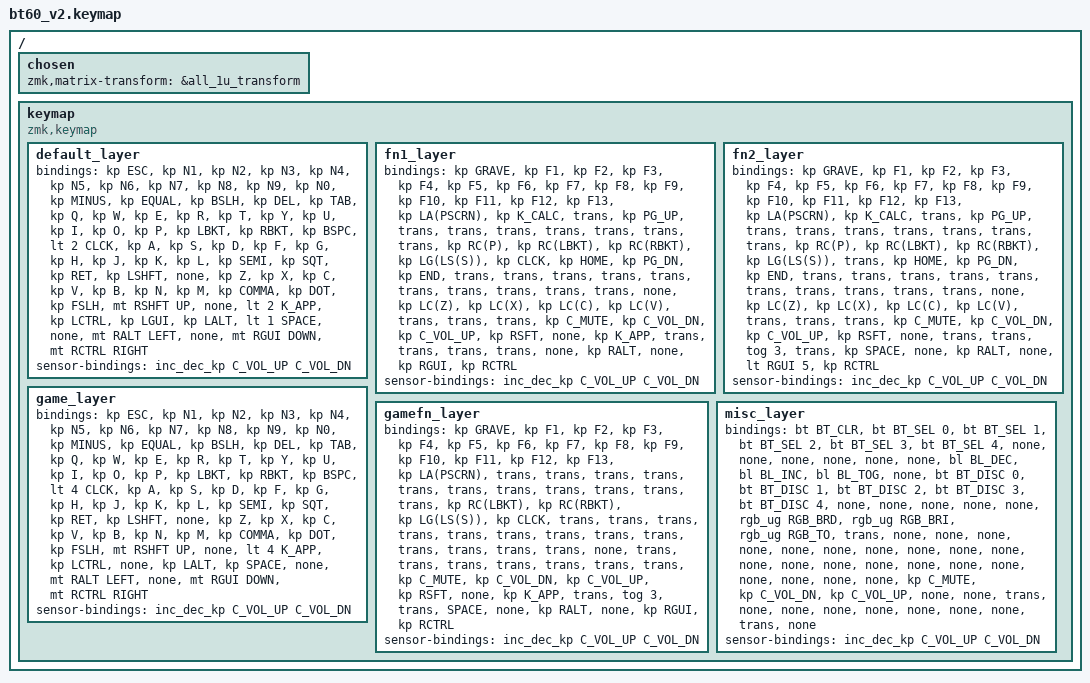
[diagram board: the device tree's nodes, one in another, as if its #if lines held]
#include <behaviors.dtsi>
#include <dt-bindings/zmk/keys.h>
#include <dt-bindings/zmk/bt.h>
#include <dt-bindings/zmk/rgb.h>
#include <dt-bindings/zmk/backlight.h>

#define ALL_1U
#define DEFAULT 0
#define FN1 1
#define FN2 2
#define GAME 3
#define GAMEFN 4
#define MISC 5

/ {
  chosen {
  #ifdef ALL_1U
    zmk,matrix-transform = &all_1u_transform;
  #else
  #error "Layout not defined, please define a layout by uncommenting the appropriate line in bt60_v2.keymap"
  #endif
  };

  keymap {
    compatible = "zmk,keymap";
    #ifdef ANSI
    default_layer {
        // ------------------------------------------------------------------------------------------0
        // | ESC |  1  |  2  |  3  |  4  |  5  |  6  |  7  |  8  |  9  |  0  |  -  |  =  |  \  | DEL |
        // | TAB   |  Q  |  W  |  E  |  R  |  T  |  Y  |  U  |  I  |  O  |  P  |  [  |  ]  |   BSPC  |
        // |  2,CAPS  |  A  |  S  |  D  |  F  |  G  |  H  |  J  |  K  |  L  |  ;  |  '  |    ENTER   |
        // | SHFT |NONE|  Z  |  X  |  C  |  V  |  B  |  N  |  M  |  ,  |  .  | / | SHFT, UP | NONE |  2,APP |
        // |  CTL  |  WIN  |  ALT  |     1,SPACE      | NONE| ALT,LEFT | NONE | WIN,DOWN | CTL,RIGHT |
        // ------------------------------------------------------------------------------------------
      bindings = <
        &kp ESC &kp N1 &kp N2 &kp N3 &kp N4 &kp N5 &kp N6 &kp N7 &kp  N8   &kp  N9 &kp  N0  &kp MINUS &kp EQUAL &kp BSLH &kp DEL
        &kp TAB  &kp Q  &kp W  &kp E  &kp R  &kp T  &kp Y  &kp U  &kp  I    &kp  O  &kp  P   &kp LBKT &kp RBKT  &kp BSPC
        &lt 2 CLCK  &kp A  &kp S  &kp D  &kp F  &kp G  &kp H  &kp J  &kp  K    &kp  L  &kp SEMI &kp SQT           &kp RET
        &kp LSHFT &none  &kp Z  &kp X  &kp C  &kp V  &kp B  &kp N  &kp M  &kp COMMA &kp DOT &kp FSLH    &mt RSHFT UP  &none &lt 2 K_APP
        &kp LCTRL &kp LGUI &kp LALT            &lt 1 SPACE                           &none &mt RALT LEFT &none &mt RGUI DOWN &mt RCTRL RIGHT
      >;
      sensor-bindings = <&inc_dec_kp C_VOL_UP C_VOL_DN>;
    };
    fn1_layer {
        // ------------------------------------------------------------------------------------------1
        // |GRAVE| F1  | F2  | F3  | F4  | F5  | F6  | F7  | F8  | F9  | F10 | F11 | F12 | F13 | A_PSCR |
        // | CALC  |  Q  |  PGUP  |  E  | R | T |  Y  |  U  | I |  O  | C_P | [ | ] | WIN+SHFT+S  |
        // | CAPS  |  HOME  |  PGDN  |  END  | F | G |  H  |  J  |  K  |  L  | ; | ' |      ENTER     |
        // | SHFT |NONE| C_Z | C_X | C_C | C_V | B |  N  |  M  |  MUTE  | VOLDN | VOLUP | SHFT| NONE | APP  |
        // | CTRL| WIN|  ALT  |           SPACE              | NONE| ALT | NONE |WIN| CTRL|
        // ------------------------------------------------------------------------------------------
      bindings = <
        &kp GRAVE &kp F1 &kp F2 &kp F3 &kp F4 &kp F5 &kp F6 &kp F7 &kp  F8   &kp  F9 &kp  F10  &kp F11 &kp F12   &kp F13 &kp LA(PSCRN)
        &kp K_CALC &trans &kp PG_UP &trans &trans &trans &trans &trans &trans &trans &kp RC(P) &kp RC(LBKT) &kp RC(RBKT) &kp LG(LS(S))
        &kp CLCK    &kp HOME &kp PG_DN &kp END &trans &trans &trans &trans &trans &trans &trans  &trans   &trans
        &trans &none &kp LC(Z) &kp LC(X) &kp LC(C) &kp LC(V) &trans &trans &trans &kp C_MUTE &kp C_VOL_DN &kp C_VOL_UP &kp RSFT &none &kp K_APP
        &trans &trans  &trans              &trans                            &none  &kp RALT &none   &kp RGUI &kp RCTRL
      >;
      sensor-bindings = <&inc_dec_kp C_VOL_UP C_VOL_DN>;
    };
    fn2_layer {
        // ------------------------------------------------------------------------------------------2
        // |GRAVE| F1  | F2  | F3  | F4  | F5  | F6  | F7  | F8  | F9  | F10 | F11 | F12 | F13 | A_PSCR |
        // | CALC  |  Q  |  PGUP  |  E  | R | T |  Y  |  U  | I |  O  | C_P | [ | ] | WIN+SHFT+S  |
        // | CAPS  |  HOME  |  PGDN  |  END  | F | G |  H  |  J  |  K  |  L  | ; | ' |      ENTER     |
        // | SHFT |NONE| C_Z | C_X | C_C | C_V | B |  N  |  M  |  MUTE  | VOLDN | VOLUP | SHFT| NONE | APP  |
        // | CTRL| 3 |  ALT  |           SPACE              | NONE| ALT | NONE |5,WIN| CTRL|
        // ------------------------------------------------------------------------------------------
      bindings = <
        &kp GRAVE &kp F1 &kp F2 &kp F3 &kp F4 &kp F5 &kp F6 &kp F7 &kp  F8   &kp  F9 &kp  F10  &kp F11 &kp F12   &kp F13 &kp LA(PSCRN)
        &kp K_CALC &trans &kp PG_UP &trans &trans &trans &trans &trans &trans &trans &kp RC(P) &kp RC(LBKT) &kp RC(RBKT) &kp LG(LS(S))
        &trans    &kp HOME &kp PG_DN &kp END &trans &trans &trans &trans &trans &trans &trans  &trans   &trans
        &trans &none &kp LC(Z) &kp LC(X) &kp LC(C) &kp LC(V) &trans &trans &trans &kp C_MUTE &kp C_VOL_DN &kp C_VOL_UP &kp RSFT &none &trans
        &trans &tog 3  &trans              &kp SPACE                            &none  &kp RALT &none   &lt RGUI 5 &kp RCTRL
      >;
      sensor-bindings = <&inc_dec_kp C_VOL_UP C_VOL_DN>;
    };
    game_layer {
        // ------------------------------------------------------------------------------------------3
        // | ESC |  1  |  2  |  3  |  4  |  5  |  6  |  7  |  8  |  9  |  0  |  -  |  =  |  \  | DEL |
        // | TAB   |  Q  |  W  |  E  |  R  |  T  |  Y  |  U  |  I  |  O  |  P  |  [  |  ]  |   BSPC  |
        // |  4,CAPS  |  A  |  S  |  D  |  F  |  G  |  H  |  J  |  K  |  L  |  ;  |  '  |    ENTER   |
        // | SHFT |NONE|  Z  |  X  |  C  |  V  |  B  |  N  |  M  |  ,  |  .  | / | SHFT, UP | NONE |  4,APP |
        // |  CTL  |  NONE  |  ALT  |     SPACE      | NONE| ALT,LEFT | NONE | WIN,DOWN | CTL,RIGHT |
        // ------------------------------------------------------------------------------------------
      bindings = <
        &kp ESC &kp N1 &kp N2 &kp N3 &kp N4 &kp N5 &kp N6 &kp N7 &kp  N8   &kp  N9 &kp  N0  &kp MINUS &kp EQUAL &kp BSLH &kp DEL
        &kp TAB  &kp Q  &kp W  &kp E  &kp R  &kp T  &kp Y  &kp U  &kp  I    &kp  O  &kp  P   &kp LBKT &kp RBKT  &kp BSPC
        &lt 4 CLCK  &kp A  &kp S  &kp D  &kp F  &kp G  &kp H  &kp J  &kp  K    &kp  L  &kp SEMI &kp SQT           &kp RET
        &kp LSHFT &none  &kp Z  &kp X  &kp C  &kp V  &kp B  &kp N  &kp M  &kp COMMA &kp DOT &kp FSLH    &mt RSHFT UP  &none &lt 4 K_APP
        &kp LCTRL &none &kp LALT            &kp SPACE                           &none &mt RALT LEFT &none &mt RGUI DOWN &mt RCTRL RIGHT
      >;
      sensor-bindings = <&inc_dec_kp C_VOL_UP C_VOL_DN>;
    };
    gamefn_layer {
        // ------------------------------------------------------------------------------------------4
        // |GRAVE| F1  | F2  | F3  | F4  | F5  | F6  | F7  | F8  | F9  | F10 | F11 | F12 | F13 | A_PSCR |
        // | TAB  |  Q  |  W  |  E  | R | T |  Y  |  U  | I |  O  | P | C[ | C] | WIN+SHFT+S  |
        // | CAPS  |  A  |  S  |  D  | F | G |  H  |  J  |  K  |  L  | ; | ' |      ENTER     |
        // | SHFT |NONE| Z | X | C | V | B |  N  |  M  |  MUTE  | VOLDN | VOLUP | SHFT| NONE | APP  |
        // | CTRL| 0 |  ALT  |           SPACE              | NONE| ALT | NONE |WIN| CTRL|
        // ------------------------------------------------------------------------------------------
      bindings = <
        &kp GRAVE &kp F1 &kp F2 &kp F3 &kp F4 &kp F5 &kp F6 &kp F7 &kp  F8   &kp  F9 &kp  F10  &kp F11 &kp F12   &kp F13 &kp LA(PSCRN)
        &trans &trans &trans &trans &trans &trans &trans &trans &trans &trans &trans &kp RC(LBKT) &kp RC(RBKT) &kp LG(LS(S))
        &kp CLCK    &trans &trans &trans &trans &trans &trans &trans &trans &trans &trans  &trans   &trans
        &trans &none &trans &trans &trans &trans &trans &trans &trans &kp C_MUTE &kp C_VOL_DN &kp C_VOL_UP &kp RSFT &none &kp K_APP
        &trans &tog 3  &trans              &SPACE                           &none  &kp RALT &none   &kp RGUI &kp RCTRL
      >;
      sensor-bindings = <&inc_dec_kp C_VOL_UP C_VOL_DN>;
    };
    misc_layer {
        // ------------------------------------------------------------------------------------------4
        // |BTCLR| BT0  | BT1  | BT2  | BT3  | BT4  | F6  | F7  | F8  | F9  | F10 | F11 | BL_DEC | BL_INC | BL_TOG |
        // | TAB  |  Q  |  W  |  E  | R | T |  Y  |  U  | I |  O  | P | RGB_BRD | RGB_BRI | RGB_TOG  |
        // | CAPS  |  A  |  S  |  D  | F | G |  H  |  J  |  K  |  L  | ; | ' |      ENTER     |
        // | SHFT |NONE| Z | X | C | V | B |  N  |  M  |  MUTE  | VOLDN | VOLUP | SHFT| NONE | APP  |
        // | CTRL| 0 |  ALT  |           SPACE              | NONE| ALT | NONE |WIN| CTRL|
        // ------------------------------------------------------------------------------------------
      bindings = <
        &bt BT_CLR &bt BT_SEL 0 &bt BT_SEL 1 &bt BT_SEL 2 &bt BT_SEL 3 &bt BT_SEL 4 &none &none &none   &none &none  &none &bl BL_DEC   &bl BL_INC &bl BL_TOG
        &none &bt BT_DISC 0 &bt BT_DISC 1 &bt BT_DISC 2 &bt BT_DISC 3 &bt BT_DISC 4 &none &none &none &none &none &rgb_ug RGB_BRD &rgb_ug RGB_BRI &rgb_ug RGB_TO
        &trans    &none &none &none &none &none &none &none &none &none &none  &none   &none
        &none &none &none &none &none &none &none &none &none &kp C_MUTE &kp C_VOL_DN &kp C_VOL_UP &none &none &trans
        &none &none  &none              &none                           &none  &none &none   &trans &none
      >;
      sensor-bindings = <&inc_dec_kp C_VOL_UP C_VOL_DN>;
    };
    #else
    #error "Layout not defined, please define a layout by uncommenting the appropriate line in bt60_v2.keymap"
    #endif

  };
};
